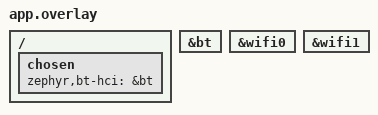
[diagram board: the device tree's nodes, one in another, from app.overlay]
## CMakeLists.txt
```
# SPDX-License-Identifier: Apache-2.0
cmake_minimum_required(VERSION 3.20.0)
find_package(Zephyr REQUIRED HINTS $ENV{ZEPHYR_BASE})
project(nu87_lcd_gateway)
if(CONFIG_GATEWAY_USB_HOST)
  target_sources(app PRIVATE src/usb_host.c)
endif()
if(CONFIG_GATEWAY_IMU)
  target_include_directories(app PRIVATE ../nu87_imu_bringup/include)
  target_sources(app PRIVATE src/imu_live.c ../nu87_imu_bringup/src/imu_device.c)
endif()
target_include_directories(app PRIVATE
  include
  ${ZEPHYR_BASE}/drivers/wifi/ameba
  ../wireless_lcd_common/include
  ../wireless_lcd_common/dfu
)
target_sources(app PRIVATE
  src/main.c
  src/wifi.c
  src/timer_core.c
  src/ameba_timer_thread.c
  src/ameba_irq.c
  src/radio_diagnostics.c
  src/hci_transport_diagnostics.c
  src/ameba_coex_scan.c
  src/http_server.c
  src/http_io.c
  src/http_parse.c
)
if(CONFIG_GATEWAY_NU40_KIT)
  target_sources(app PRIVATE src/ble_kit.c src/smp_relay.c src/alarm_relay.c src/robot_state.c src/ota_disabled.c)
else()
  target_sources(app PRIVATE src/ble_link.c src/ota.c
    ../wireless_lcd_common/dfu/legacy_dfu_client.c)
endif()

# Vendor timer callbacks may take mutexes. Keep them on a private daemon thread
# instead of the pinned SDK's k_timer interrupt callbacks, without editing SDKs.
foreach(timer_api create create_static delete delete_static start stop change_period is_timer_active get_id)
  zephyr_ld_options(-Wl,--wrap=rtos_timer_${timer_api})
endforeach()
# Keep the vendor's strong init_timer_wrapper: it initializes its callback map.

# Realtek HCI uses hardware priority 7; Zephyr reserves one priority level.
zephyr_ld_options(-Wl,--wrap=arch_irq_connect_dynamic)
# Retain the vendor error and heap snapshots before Zephyr maps it to -EAGAIN.
zephyr_ld_options(-Wl,--wrap=wifi_connect_zephyr)
# Observe RF calibration and raw RX counts without changing SDK behavior.
zephyr_ld_options(-Wl,--wrap=rtk_coex_btc_bt_rfk)
zephyr_ld_options(-Wl,--wrap=bt_coex_process_rx_frame)

# Count UART frames before the vendor H4 event pool, preserving the wire bytes.
zephyr_ld_options(-Wl,--wrap=hci_uart_read)
zephyr_ld_options(-Wl,--wrap=UART_LineStatusGet)
```

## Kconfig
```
# SPDX-License-Identifier: Apache-2.0
mainmenu "NU87 Wi-Fi to NU40 BLE LCD gateway"
source "Kconfig.zephyr"
menu "LCD gateway settings"
config GATEWAY_USB_HOST
	bool "Use the on-board USB-UART for HostPC data and control"
	depends on GATEWAY_NU40_KIT
	default n
	help
	  Use authenticated CRC-protected serial RPC instead of the HTTP listener.
	  The shared Realtek RF initializes without AP association or DHCP.
config GATEWAY_IMU
	bool "Read an attached LSM6DS3/LSM6DS3TR-C over PA25/PA26"
	select I2C
	select GPIO
	select PINCTRL
	default n
choice GATEWAY_DISPLAY_PROTOCOL
	prompt "NU40 display firmware protocol"
	default GATEWAY_LCD_LEGACY
config GATEWAY_LCD_LEGACY
	bool "MZSZ-LCD / verified S140 legacy DFU"
config GATEWAY_NU40_KIT
	bool "NU40-KIT-DISPLAY with optional voice and authenticated SMP"
endchoice
config GATEWAY_PEER_ADDRESS
	string "Explicit NU40 LCD Bluetooth address (AA:BB:CC:DD:EE:FF)"
	default ""
config GATEWAY_PEER_ADDRESS_TYPE
	string "LCD Bluetooth address type (random or public)"
	default "random"
config GATEWAY_DFU_ADDRESS
	string "Explicit bootloader Bluetooth address; empty requires same LCD address"
	default ""
config GATEWAY_DFU_ADDRESS_TYPE
	string "Bootloader Bluetooth address type (random or public)"
	default "random"
config GATEWAY_WIFI_SSID
	string "Isolated test Wi-Fi SSID"
	default ""
config GATEWAY_WIFI_PSK
	string "Disposable test Wi-Fi PSK"
	default ""
config GATEWAY_WIFI_CHANNEL
	int "2.4 GHz AP channel (0 scans all channels)"
	range 0 14
	default 0
	help
	  Try the AP's observed channel on the first association attempt. Later
	  attempts scan all channels so a restarted hotspot can change channel.
	  Leave zero to scan all channels from the first attempt.
choice GATEWAY_WIFI_SECURITY
	prompt "Wi-Fi security"
	default GATEWAY_WIFI_SECURITY_OPEN
config GATEWAY_WIFI_SECURITY_OPEN
	bool "Open isolated test network"
config GATEWAY_WIFI_SECURITY_PSK
	bool "WPA2-PSK isolated test network"
endchoice
config GATEWAY_ALLOW_INSECURE_TEST_PSK
	bool "Acknowledge the AmebaD unverified entropy source for test WPA2"
	depends on GATEWAY_WIFI_SECURITY_PSK
	default n
config GATEWAY_WIFI_CONNECT_DELAY_MS
	int
	default 500
config GATEWAY_WIFI_CONNECT_RETRY_SECONDS
	int
	default 10
config GATEWAY_WIFI_CONNECT_TIMEOUT_SECONDS
	int
	default 60
config GATEWAY_WIFI_WORK_STACK_SIZE
	int
	default 4096
config GATEWAY_WIFI_WORK_PRIORITY
	int
	default 7
config GATEWAY_TIMER_STACK_SIZE
	int "Vendor software timer daemon stack size"
	range 2048 16384
	default 6144
config GATEWAY_HTTP_PORT
	int "HTTP port"
	range 1 65535
	default 8080
config GATEWAY_API_TOKEN
	string "Local API bearer token; empty disables mutating HTTP requests"
	default ""
config GATEWAY_NU40_PASSKEY
	string "Private six-digit NU40 pairing passkey (empty disables SMP relay)"
	depends on GATEWAY_NU40_KIT
	default ""
config GATEWAY_LOG_LEVEL
	int
	range 0 4
	default 3
endmenu
```

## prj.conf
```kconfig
CONFIG_CONSOLE=y
CONFIG_SERIAL=y
CONFIG_UART_CONSOLE=y
CONFIG_PRINTK=y
CONFIG_LOG=y
CONFIG_LOG_DEFAULT_LEVEL=3
# HTTP parsing and the vendor's synchronous Wi-Fi transmit path share main.
CONFIG_MAIN_STACK_SIZE=12288
CONFIG_INIT_STACKS=y
CONFIG_THREAD_STACK_INFO=y
CONFIG_SYSTEM_WORKQUEUE_STACK_SIZE=2048
CONFIG_ASSERT=y
CONFIG_NETWORKING=y
CONFIG_NET_IPV4=y
CONFIG_NET_IPV6=n
CONFIG_NET_TCP=y
CONFIG_NET_UDP=y
CONFIG_NET_SOCKETS=y
CONFIG_NET_CONNECTION_MANAGER=y
# The application's Wi-Fi state machine owns disconnect/retry transitions.
CONFIG_NET_CONNECTION_MANAGER_AUTO_IF_DOWN=n
CONFIG_NET_DHCPV4=y
CONFIG_WIFI=y
CONFIG_WIFI_AMEBA=y
CONFIG_NET_L2_WIFI_MGMT=y
CONFIG_RTK_WIFI_STA_AUTO_DHCPV4=y
CONFIG_NOCACHE_MEMORY=y
CONFIG_HEAP_MEM_POOL_SIZE=65536
CONFIG_SYS_HEAP_RUNTIME_STATS=y
CONFIG_NET_PKT_RX_COUNT=10
CONFIG_NET_PKT_TX_COUNT=10
CONFIG_NET_BUF_RX_COUNT=20
CONFIG_NET_BUF_TX_COUNT=32
CONFIG_NET_MAX_CONTEXTS=10
CONFIG_NET_MAX_CONN=10
CONFIG_BT=y
CONFIG_BT_CENTRAL=y
CONFIG_BT_GATT_CLIENT=y
CONFIG_BT_MAX_CONN=1
CONFIG_BT_SMP=y
CONFIG_BT_SHELL=n
CONFIG_REALTEK_AMEBA_ZEPHYR_BT=y
CONFIG_BT_COEXIST=y
# Realtek's internal HCI UART uses dynamic IRQ registration.
CONFIG_DYNAMIC_INTERRUPTS=y
# This AmebaD port has no verified hardware entropy source. Bring-up only.
CONFIG_TEST_RANDOM_GENERATOR=y
CONFIG_BT_GATT_AUTO_DISCOVER_CCC=y
CONFIG_BT_DEVICE_NAME="MZSZ-LCD-Gateway"
CONFIG_THREAD_NAME=y
CONFIG_LOG_MODE_DEFERRED=y
CONFIG_LOG_BUFFER_SIZE=4096
CONFIG_NET_MGMT_EVENT_QUEUE_SIZE=16
CONFIG_NET_MGMT_EVENT_QUEUE_TIMEOUT=5000
# LCD writes remain <=20 bytes; optional audio notifications require MTU >=179.
CONFIG_BT_L2CAP_TX_MTU=247
CONFIG_BT_BUF_ACL_RX_SIZE=251
```

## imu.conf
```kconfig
# Real sensor only. Requires imu.overlay and the bounded repeated-START fix.
CONFIG_GATEWAY_IMU=y
```

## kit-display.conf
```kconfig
# Current mzsz94/nu40-ble-display protocol; keep its installed firmware.
# No S140 legacy DFU, power control or automatic peer selection.
CONFIG_GATEWAY_NU40_KIT=y
```

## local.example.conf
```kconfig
# Copy to ignored local.conf and fill in values. Default stays unconfigured.
# Use only an isolated test AP: the pinned AmebaD port lacks verified entropy.
CONFIG_GATEWAY_WIFI_SSID=""
CONFIG_GATEWAY_WIFI_SECURITY_OPEN=y
CONFIG_GATEWAY_API_TOKEN=""
# Explicit peer identity required; a matching advertised name is insufficient.
CONFIG_GATEWAY_PEER_ADDRESS=""
CONFIG_GATEWAY_PEER_ADDRESS_TYPE="random"
# Empty means the bootloader must have exactly the same address/type.
# Official unbonded legacy bootloaders commonly increment the last address byte.
# Inspect the bootloader identity and configure it explicitly; no automatic
# address arithmetic or name-only trust is performed by this gateway.
CONFIG_GATEWAY_DFU_ADDRESS=""
CONFIG_GATEWAY_DFU_ADDRESS_TYPE="random"
```

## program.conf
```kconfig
# Zephyr's default console is the Ameba LogUART at 1500000 baud.
CONFIG_BUILD_OUTPUT_BIN=y
# Include pinned Realtek KM0 firmware and generate the runnable merged image.
CONFIG_SOC_AMEBA_NP_IMAGE=y
```

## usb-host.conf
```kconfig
# USB owns the API; initialize the shared RF without joining an access point.
CONFIG_GATEWAY_USB_HOST=y
# Keep vendor startup diagnostics visible until RF is ready. usb_host.c then
# disables this backend before sending framed traffic, preventing interleaving.
CONFIG_LOG_BACKEND_UART=y
CONFIG_LOG_PRINTK=y
```

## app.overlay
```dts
/ {
	chosen { zephyr,bt-hci = &bt; };
};
&bt { status = "okay"; };
&wifi0 { status = "okay"; };
&wifi1 { status = "okay"; };
```

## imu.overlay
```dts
/* SPDX-License-Identifier: Apache-2.0 */
#include <zephyr/dt-bindings/pinctrl/amebad-pinctrl.h>
&pinctrl {
	imu_i2c_default: imu_i2c_default {
		group1 {
			pinmux = <AMEBA_PINMUX('A', 25, AMEBA_I2C)>,
				 <AMEBA_PINMUX('A', 26, AMEBA_I2C)>;
			bias-pull-up;
		};
	};
};
&i2c0 {
	status = "okay";
	clock-frequency = <I2C_BITRATE_STANDARD>;
	pinctrl-0 = <&imu_i2c_default>;
	pinctrl-names = "default";
};
```

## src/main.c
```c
/* SPDX-License-Identifier: Apache-2.0 */
#include "gateway_link.h"
#include "gateway_http.h"
#include "gateway_imu.h"
#include "gateway_usb.h"
#include <zephyr/kernel.h>
#include <zephyr/logging/log.h>
LOG_MODULE_REGISTER(lcd_gateway, LOG_LEVEL_INF);
int main(void)
{
	LOG_INF("NU87 Wi-Fi/BLE LCD gateway: isolated test LAN only");
	gateway_imu_start();
	int rc = gateway_radio_init();
	if (rc) { LOG_ERR("Radio initialization failed: %d", rc); return rc; }
#if defined(CONFIG_GATEWAY_USB_HOST)
	gateway_usb_run();
#else
	gateway_http_run();
#endif
	return 0;
}
```

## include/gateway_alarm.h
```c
/* SPDX-License-Identifier: Apache-2.0 */
#ifndef WALLABY_GATEWAY_ALARM_H
#define WALLABY_GATEWAY_ALARM_H
#include <stdbool.h>
#include <stddef.h>
#include <stdint.h>
struct bt_conn;
int gateway_alarm_prepare(struct bt_conn *conn);
void gateway_alarm_disconnected(struct bt_conn *conn);
bool gateway_alarm_drained(void);
int gateway_alarm_set(bool active);
int gateway_alarm_status(char *json, size_t capacity);
#endif
```

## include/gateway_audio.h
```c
/* SPDX-License-Identifier: Apache-2.0 */
#ifndef WALLABY_GATEWAY_AUDIO_H
#define WALLABY_GATEWAY_AUDIO_H
#include <stdbool.h>
#include <stddef.h>
#include <stdint.h>
#include <string.h>

#define GATEWAY_AUDIO_FRAME_SIZE 176U
#define GATEWAY_AUDIO_RING_FRAMES 64U
#define GATEWAY_AUDIO_DRAIN_FRAMES 32U
#define GATEWAY_AUDIO_MIN_MTU 179U
#define GATEWAY_AUDIO_CTRL_UUID_VAL BT_UUID_128_ENCODE(0x90e2c003, 0x3c0d, 0x4ef3, 0x9d78, 0x574cd1a64087)
#define GATEWAY_AUDIO_DATA_UUID_VAL BT_UUID_128_ENCODE(0x90e2c004, 0x3c0d, 0x4ef3, 0x9d78, 0x574cd1a64087)

/* Caller supplies synchronization. Independent ADPCM frames never inherit a
 * predictor from a lost frame. No partial/truncated notifications are queued. */
struct gateway_audio_ring {
 uint8_t frames[GATEWAY_AUDIO_RING_FRAMES][GATEWAY_AUDIO_FRAME_SIZE];
 uint32_t session, next_sequence, received, dropped;
 size_t head, queued;
 bool available, running;
 int error;
};

static inline uint32_t gateway_audio_u32(const uint8_t *p)
{ return (uint32_t)p[0] | (uint32_t)p[1] << 8 | (uint32_t)p[2] << 16 | (uint32_t)p[3] << 24; }
static inline void gateway_audio_add(uint32_t *value, uint32_t amount)
{ *value = UINT32_MAX - *value < amount ? UINT32_MAX : *value + amount; }

static inline bool gateway_audio_frame_valid(const uint8_t *p, size_t size)
{
 return p != NULL && size == GATEWAY_AUDIO_FRAME_SIZE && p[0] == 'W' && p[1] == 'A' &&
  p[2] == 1 && p[3] == 0 && p[14] <= 88 && p[15] == 0 && (p[175] & 0xf0) == 0;
}

static inline void gateway_audio_reset(struct gateway_audio_ring *r, uint32_t session)
{
 r->session = session; r->next_sequence = 0; r->received = r->dropped = 0;
 r->head = r->queued = 0; r->running = true; r->error = 0;
}

static inline bool gateway_audio_push(struct gateway_audio_ring *r, const uint8_t *p, size_t size)
{
 if (!r->running) { return false; }
 if (!gateway_audio_frame_valid(p, size) || gateway_audio_u32(p + 4) != r->session) {
  gateway_audio_add(&r->dropped, 1); return false;
 }
 uint32_t sequence = gateway_audio_u32(p + 8);
 /* Sessions are bounded; never let sequence wrap re-admit stale data. */
 if (sequence < r->next_sequence || sequence == UINT32_MAX) {
  gateway_audio_add(&r->dropped, 1); return false;
 }
 gateway_audio_add(&r->dropped, sequence - r->next_sequence);
 r->next_sequence = sequence + 1;
 gateway_audio_add(&r->received, 1);
 if (r->queued == GATEWAY_AUDIO_RING_FRAMES) {
  r->head = (r->head + 1) % GATEWAY_AUDIO_RING_FRAMES;
  r->queued--; gateway_audio_add(&r->dropped, 1);
 }
 memcpy(r->frames[(r->head + r->queued) % GATEWAY_AUDIO_RING_FRAMES], p, size);
 r->queued++;
 return true;
}

static inline size_t gateway_audio_pop(struct gateway_audio_ring *r, uint8_t *out, size_t capacity)
{
 size_t count = capacity / GATEWAY_AUDIO_FRAME_SIZE;
 if (count > GATEWAY_AUDIO_DRAIN_FRAMES) { count = GATEWAY_AUDIO_DRAIN_FRAMES; }
 if (count > r->queued) { count = r->queued; }
 if (out == NULL) { return 0; }
 for (size_t i = 0; i < count; i++) {
  memcpy(out + i * GATEWAY_AUDIO_FRAME_SIZE, r->frames[r->head], GATEWAY_AUDIO_FRAME_SIZE);
  r->head = (r->head + 1) % GATEWAY_AUDIO_RING_FRAMES;
 }
 r->queued -= count;
 return count * GATEWAY_AUDIO_FRAME_SIZE;
}

int gateway_audio_status(char *json, size_t capacity);
int gateway_audio_start(uint32_t session);
int gateway_audio_stop(void);
int gateway_audio_pause(void);
bool gateway_audio_available(void);
size_t gateway_audio_chunk(uint8_t *data, size_t capacity);
#endif
```

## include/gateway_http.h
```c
/* SPDX-License-Identifier: Apache-2.0 */
#ifndef GATEWAY_HTTP_H
#define GATEWAY_HTTP_H
#include <stddef.h>
#include <stdint.h>
#include <stdbool.h>
#define HTTP_HEADER_CAPACITY 1536
#define OTA_DESCRIPTOR_SIZE 80
struct http_request {
	char method[8];
	char path[96];
	char bearer[129];
	size_t content_length;
	bool keep_alive;
};
/* Strict request framing; bounded sequential keep-alive, no chunking. */
int http_parse_request(char *header, struct http_request *request);
int http_send_all(int socket, const void *data, size_t length);
int http_read_exact(int socket, void *data, size_t length);
int http_read_before(int socket, void *data, size_t length, int64_t deadline);
int http_fetch_image(uint32_t ipv4, uint16_t port, const char *id,
		     uint32_t offset, uint32_t total, uint8_t *data, size_t length);
void gateway_http_run(void);
typedef void (*gateway_api_reply_fn)(void *user, int code, const void *body,
				     size_t length, const char *type);
/* The USB build uses the same authenticated routes. Only one transport owns
 * the handler's static buffers in a given firmware build. */
bool gateway_api_authenticated(const char *token);
void gateway_api_execute(const char *method, const char *path, const uint8_t *body,
			 size_t length, gateway_api_reply_fn reply, void *user);
int gateway_ota_start(uint32_t ipv4, const uint8_t descriptor[OTA_DESCRIPTOR_SIZE]);
int gateway_ota_cancel(void);
bool gateway_ota_busy(void);
void gateway_ota_status(char *buffer, size_t capacity);
#endif
```

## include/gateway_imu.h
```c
/* SPDX-License-Identifier: Apache-2.0 */
#ifndef GATEWAY_IMU_H
#define GATEWAY_IMU_H
#include <stddef.h>
#include <zephyr/sys/printk.h>
#ifdef CONFIG_GATEWAY_IMU
void gateway_imu_start(void);
int gateway_imu_status(char *buffer, size_t capacity);
#else
static inline void gateway_imu_start(void) {}
static inline int gateway_imu_status(char *buffer, size_t capacity)
{
	return snprintk(buffer, capacity, "{\"configured\":false,\"ready\":false,"
		       "\"fresh\":false,\"source\":\"nu87-i2c\"}");
}
#endif
#endif
```

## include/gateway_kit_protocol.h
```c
/* SPDX-License-Identifier: Apache-2.0 */
/* Vendored from https://github.com/mzsz94/nu40-ble-display
 * commit 230a1300d121b3bf25d3125a0cf247679148a40a, shared/ble_display_protocol.h.
 * Original framing helper is unchanged; local filename differs.
 * See NU40-KIT-LICENSE.txt for the upstream Apache-2.0 license.
 */
#ifndef BLE_DISPLAY_PROTOCOL_H_
#define BLE_DISPLAY_PROTOCOL_H_

#include <stdbool.h>
#include <stddef.h>
#include <stdint.h>
#include <string.h>

/* No larger MTU is needed: every write fits the default 20-byte ATT payload. */
#define BLE_DISPLAY_VERSION 1U
#define BLE_DISPLAY_TEXT 1U
#define BLE_DISPLAY_ACK 2U
#define BLE_DISPLAY_CHUNK 14U
#define BLE_DISPLAY_MAX_TEXT 84U
#define BLE_DISPLAY_FRAME_MAX 20U
#define BLE_DISPLAY_ACK_SIZE 5U
#define BLE_DISPLAY_TIMEOUT_MS 2000U
#define BLE_DISPLAY_COLUMNS 21U
#define BLE_DISPLAY_ROWS 4U

#define BLE_DISPLAY_UUID_SERVICE_VAL \
	BT_UUID_128_ENCODE(0x90e2c000, 0x3c0d, 0x4ef3, 0x9d78, 0x574cd1a64087)
#define BLE_DISPLAY_UUID_ACK_VAL \
	BT_UUID_128_ENCODE(0x90e2c001, 0x3c0d, 0x4ef3, 0x9d78, 0x574cd1a64087)
#define BLE_DISPLAY_UUID_TEXT_VAL \
	BT_UUID_128_ENCODE(0x90e2c002, 0x3c0d, 0x4ef3, 0x9d78, 0x574cd1a64087)

enum ble_display_result {
	BLE_DISPLAY_WAIT = 0,
	BLE_DISPLAY_COMPLETE = 1,
	BLE_DISPLAY_INVALID = -1,
	BLE_DISPLAY_ORDER = -2,
	BLE_DISPLAY_EXPIRED = -3,
};

enum ble_display_status {
	BLE_DISPLAY_OK = 0,
	BLE_DISPLAY_BAD_TEXT = 1,
	BLE_DISPLAY_OLED_ERROR = 2,
	BLE_DISPLAY_BUSY = 3,
};

struct ble_display_rx {
	char text[BLE_DISPLAY_MAX_TEXT + 1];
	uint32_t started_ms;
	uint16_t sequence;
	uint8_t total;
	uint8_t received;
	bool active;
};

static inline uint16_t ble_display_u16(const uint8_t *bytes)
{
	return (uint16_t)bytes[0] | ((uint16_t)bytes[1] << 8);
}

static inline bool ble_display_valid_text(const char *text, size_t length)
{
	if (text == NULL || length == 0 || length > BLE_DISPLAY_MAX_TEXT) {
		return false;
	}
	for (size_t i = 0; i < length; i++) {
		uint8_t c = (uint8_t)text[i];

		if (c != '\n' && (c < 32 || c > 126)) {
			return false;
		}
	}
	return true;
}

/* Render only complete messages that fit the 128x32 display's 6x8 font. */
static inline bool ble_display_split_lines(const char *text, size_t length,
					   char lines[BLE_DISPLAY_ROWS][BLE_DISPLAY_COLUMNS + 1])
{
	size_t row = 0, column = 0;

	if (lines == NULL || !ble_display_valid_text(text, length)) {
		return false;
	}
	memset(lines, 0, BLE_DISPLAY_ROWS * (BLE_DISPLAY_COLUMNS + 1));
	for (size_t i = 0; i < length; i++) {
		if (text[i] == '\n') {
			row++;
			column = 0;
			continue;
		}
		if (column == BLE_DISPLAY_COLUMNS) {
			row++;
			column = 0;
		}
		if (row >= BLE_DISPLAY_ROWS) {
			return false;
		}
		lines[row][column++] = text[i];
	}
	return true;
}

/* Return frame length, or zero for invalid input. */
static inline size_t ble_display_build_text(const char *text, size_t length, uint16_t sequence,
					   uint8_t chunk, uint8_t out[BLE_DISPLAY_FRAME_MAX])
{
	size_t offset = (size_t)chunk * BLE_DISPLAY_CHUNK;
	size_t payload;

	if (out == NULL || !ble_display_valid_text(text, length) || offset >= length) {
		return 0;
	}
	payload = length - offset;
	if (payload > BLE_DISPLAY_CHUNK) {
		payload = BLE_DISPLAY_CHUNK;
	}
	out[0] = BLE_DISPLAY_VERSION;
	out[1] = BLE_DISPLAY_TEXT;
	out[2] = sequence & 0xff;
	out[3] = sequence >> 8;
	out[4] = chunk;
	out[5] = length;
	memcpy(out + 6, text + offset, payload);
	return 6 + payload;
}

static inline void ble_display_rx_reset(struct ble_display_rx *rx)
{
	memset(rx, 0, sizeof(*rx));
}

/* A complete text is exposed only after every in-order fragment is received. */
static inline enum ble_display_result ble_display_receive(struct ble_display_rx *rx,
							  const uint8_t *frame, size_t length,
							  uint32_t now_ms)
{
	size_t offset, payload;
	uint16_t sequence;
	uint8_t total, chunk;

	if (rx == NULL) {
		return BLE_DISPLAY_INVALID;
	}
	if (frame == NULL || length < 7 || length > BLE_DISPLAY_FRAME_MAX ||
	    frame[0] != BLE_DISPLAY_VERSION || frame[1] != BLE_DISPLAY_TEXT) {
		rx->active = false;
		return BLE_DISPLAY_INVALID;
	}
	sequence = ble_display_u16(frame + 2);
	chunk = frame[4];
	total = frame[5];
	offset = (size_t)chunk * BLE_DISPLAY_CHUNK;
	if (total == 0 || total > BLE_DISPLAY_MAX_TEXT || offset >= total) {
		rx->active = false;
		return BLE_DISPLAY_INVALID;
	}
	payload = total - offset;
	if (payload > BLE_DISPLAY_CHUNK) {
		payload = BLE_DISPLAY_CHUNK;
	}
	if (length != 6 + payload ||
	    !ble_display_valid_text((const char *)frame + 6, payload)) {
		rx->active = false;
		return BLE_DISPLAY_INVALID;
	}
	if (chunk == 0) {
		rx->sequence = sequence;
		rx->total = total;
		rx->received = 0;
		rx->started_ms = now_ms;
		rx->active = true;
	} else {
		if (!rx->active || rx->sequence != sequence || rx->total != total ||
		    rx->received != offset) {
			rx->active = false;
			return BLE_DISPLAY_ORDER;
		}
		if ((uint32_t)(now_ms - rx->started_ms) > BLE_DISPLAY_TIMEOUT_MS) {
			rx->active = false;
			return BLE_DISPLAY_EXPIRED;
		}
	}
	memcpy(rx->text + offset, frame + 6, payload);
	rx->received += payload;
	if (rx->received == rx->total) {
		rx->text[rx->total] = '\0';
		rx->active = false;
		return BLE_DISPLAY_COMPLETE;
	}
	return BLE_DISPLAY_WAIT;
}

static inline void ble_display_build_ack(uint16_t sequence, uint8_t status,
					 uint8_t out[BLE_DISPLAY_ACK_SIZE])
{
	out[0] = BLE_DISPLAY_VERSION;
	out[1] = BLE_DISPLAY_ACK;
	out[2] = sequence & 0xff;
	out[3] = sequence >> 8;
	out[4] = status;
}

static inline bool ble_display_parse_ack(const uint8_t *frame, size_t length,
					 uint16_t *sequence, uint8_t *status)
{
	if (frame == NULL || length != BLE_DISPLAY_ACK_SIZE ||
	    frame[0] != BLE_DISPLAY_VERSION || frame[1] != BLE_DISPLAY_ACK ||
	    frame[4] > BLE_DISPLAY_BUSY || sequence == NULL || status == NULL) {
		return false;
	}
	*sequence = ble_display_u16(frame + 2);
	*status = frame[4];
	return true;
}

#endif /* BLE_DISPLAY_PROTOCOL_H_ */
```

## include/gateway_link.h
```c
/* SPDX-License-Identifier: Apache-2.0 */
#ifndef MZSZ_GATEWAY_LINK_H
#define MZSZ_GATEWAY_LINK_H
#include <stdbool.h>
#include <stddef.h>
#include <stdint.h>
#include "lcd_protocol.h"
#if defined(CONFIG_GATEWAY_NU40_KIT)
#include "gateway_audio.h"
#include "gateway_smp.h"
#include "gateway_alarm.h"
#include "gateway_robot.h"
#endif

struct gateway_state {
	bool wifi_connected;
	char wifi_ipv4[16];
	bool ble_configured;
	bool ble_connected;
	bool lcd_ready;
	bool dfu_ready;
	char peer_addr[32];
	int last_error;
};

/* RX-context callback: copy/queue the data and return; never block here. */
typedef void (*gateway_dfu_notify_fn)(const uint8_t *data, size_t len, void *user);
int gateway_radio_init(void);
/* Diagnostic stage must be a non-sensitive, static string. */
void gateway_radio_diagnostics(const char *stage);
void gateway_radio_coex_diagnostics(void);
int gateway_hci_diagnostics(char *json, size_t capacity);
int gateway_hci_transport_diagnostics(char *json, size_t capacity);
int gateway_coex_scan_diagnostics(char *json, size_t capacity);
/* Observe HCI framing only; vendor coexistence work runs on its own thread. */
void gateway_coex_scan_tx(uint8_t type, const uint8_t *data, uint16_t length);
void gateway_coex_scan_rx(uint8_t type, const uint8_t *data, uint16_t length);
/* H4 RX thread only: serialize native coexistence processing with reports. */
void gateway_coex_scan_rx_begin(void);
void gateway_coex_scan_rx_end(void);
void gateway_get_state(struct gateway_state *state);
/* One blocking request at a time. Success means a matching completion status
 * arrived; status[4] still carries the peripheral's LCD_RESULT_* result.
 * No automatic retry or replay is performed on timeout/disconnect.
 */
int gateway_lcd_command(const uint8_t *data, size_t len,
			uint8_t status[LCD_STATUS_SIZE], int timeout_ms);

/* NU40-KIT-DISPLAY mode: bounded discovery and explicit, fresh peer selection.
 * Candidates returns a JSON array's byte count or a negative error. Selection
 * starts connection asynchronously; display succeeds only after matching ACK.
 */
#if defined(CONFIG_GATEWAY_NU40_KIT)
int gateway_peer_candidates(char *json, size_t capacity);
int gateway_scan_diagnostics(char *json, size_t capacity);
int gateway_kit_diagnostics(char *json, size_t capacity);
/* Queue an active/passive scan-mode change; never interrupt an active peer. */
int gateway_scan_mode(const char *mode);
int gateway_select_peer(const char *address, const char *type);
int gateway_display_text(const uint8_t *text, size_t len, int timeout_ms);
#endif
int gateway_dfu_enter(void);
int gateway_dfu_control(const uint8_t *data, size_t len);
int gateway_dfu_packet(const uint8_t *data, size_t len);
void gateway_dfu_set_notify_callback(gateway_dfu_notify_fn callback, void *user);
/* Leave DFU transport mode after a finished/failed transfer. No device reset
 * or activation command is sent. Subsequent scanning targets the LCD identity.
 */
void gateway_dfu_leave(void);

/* Internal Wi-Fi module interface; also useful to the HTTP listener. */
int gateway_wifi_start(void);
bool gateway_wifi_ipv4_ready(void);
int gateway_wifi_address(char *buffer, size_t capacity);
#endif
```

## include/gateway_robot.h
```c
/* SPDX-License-Identifier: Apache-2.0 */
#ifndef WALLABY_GATEWAY_ROBOT_H
#define WALLABY_GATEWAY_ROBOT_H
#include <stdbool.h>
#include <stddef.h>
int gateway_robot_command(const char *command);
int gateway_robot_status(char *json, size_t capacity, bool accepted);
void gateway_robot_alert(bool active);
#endif
```

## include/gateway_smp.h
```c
/* SPDX-License-Identifier: Apache-2.0 */
#ifndef WALLABY_GATEWAY_SMP_H
#define WALLABY_GATEWAY_SMP_H
#include <stdbool.h>
#include <stddef.h>
#include <stdint.h>
#include <string.h>
#define GATEWAY_SMP_MAX 1024U
struct bt_conn;
struct gateway_smp_rx {
 uint8_t request[8], data[GATEWAY_SMP_MAX];
 size_t used, expected;
};
static inline size_t gateway_smp_length(const uint8_t *p)
{ return 8U + ((size_t)p[2] << 8) + p[3]; }
static inline bool gateway_smp_request_valid(const uint8_t *p, size_t size)
{
 return p != NULL && size >= 8 && size <= GATEWAY_SMP_MAX &&
  (p[0] == 0 || p[0] == 2) && p[1] == 0 && gateway_smp_length(p) == size;
}
/* 1 complete, 0 more required, 2 unrelated reply, -1 invalid framing. */
static inline int gateway_smp_receive(struct gateway_smp_rx *r, const uint8_t *p, size_t size)
{
 if (p == NULL || size == 0) { return -1; }
 if (r->used == 0) {
  if (size < 8) { return -1; }
  if (p[0] != r->request[0] + 1 || p[1] != 0 || memcmp(p + 4, r->request + 4, 4) != 0) { return 2; }
  r->expected = gateway_smp_length(p);
  if (r->expected > GATEWAY_SMP_MAX) { return -1; }
 }
 if (size > r->expected - r->used) { return -1; }
 memcpy(r->data + r->used, p, size); r->used += size;
 return r->used == r->expected ? 1 : 0;
}
int gateway_smp_prepare(struct bt_conn *conn);
int gateway_smp_auth_init(void);
void gateway_smp_disconnected(struct bt_conn *conn);
bool gateway_smp_drained(void);
bool gateway_smp_available(void);
bool gateway_smp_busy(void);
int gateway_smp_transaction(const uint8_t *request, size_t size, uint8_t *response, size_t capacity);
#endif
```

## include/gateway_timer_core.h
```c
/* SPDX-License-Identifier: Apache-2.0 */
#ifndef GATEWAY_TIMER_CORE_H
#define GATEWAY_TIMER_CORE_H

#include <stdbool.h>
#include <stdint.h>

/* All operations require the caller's lock. Only the daemon dispatches and
 * completes callbacks. Opaque handles remain valid until delete is accepted;
 * reusing a deleted handle after allocation reuses its address is caller misuse.
 */
struct gateway_timer {
	struct gateway_timer *next;
	void (*callback)(void *);
	uint32_t id;
	uint32_t interval_ms;
	uint32_t generation;
	uint32_t dispatched_generation;
	int64_t deadline_ms;
	bool periodic;
	bool active;
	bool running;
	bool retired;
};

struct gateway_timer_core {
	struct gateway_timer *head;
};

enum gateway_timer_delete_result {
	GATEWAY_TIMER_DELETE_INVALID = -1,
	GATEWAY_TIMER_DELETE_DEFERRED = 0,
	GATEWAY_TIMER_DELETE_RECLAIM = 1,
};

void gateway_timer_add(struct gateway_timer_core *core, struct gateway_timer *timer);
struct gateway_timer *gateway_timer_find(struct gateway_timer_core *core, const void *handle);
bool gateway_timer_arm(struct gateway_timer_core *core, const void *handle,
		       uint32_t interval_ms, int64_t now_ms);
bool gateway_timer_stop(struct gateway_timer_core *core, const void *handle);
enum gateway_timer_delete_result gateway_timer_retire(struct gateway_timer_core *core,
						      const void *handle);
struct gateway_timer *gateway_timer_dispatch(struct gateway_timer_core *core,
					     int64_t now_ms, int64_t *wait_ms);
bool gateway_timer_complete(struct gateway_timer_core *core, struct gateway_timer *timer,
			    int64_t now_ms);

#endif
```

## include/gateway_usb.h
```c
/* SPDX-License-Identifier: Apache-2.0 */
#ifndef WALLABY_GATEWAY_USB_H
#define WALLABY_GATEWAY_USB_H
void gateway_usb_run(void);
#endif
```

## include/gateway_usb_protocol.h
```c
/* SPDX-License-Identifier: Apache-2.0 */
#ifndef WALLABY_GATEWAY_USB_PROTOCOL_H
#define WALLABY_GATEWAY_USB_PROTOCOL_H
#include <stdbool.h>
#include <stddef.h>
#include <stdint.h>
#include <string.h>

/* COBS-delimited frames coexist with boot text. CRC covers the whole decoded
 * message. A fresh authenticated HELLO owns a session; mutations are never
 * retried. The largest response is 32 complete 176-byte microphone frames. */
#define USB_RPC_HEADER 20U
#define USB_RPC_BODY_MAX 5632U
#define USB_RPC_REQUEST_MAX 1024U
#define USB_RPC_WIRE_MAX 6144U
#define USB_RPC_REQUEST 1U
#define USB_RPC_RESPONSE 2U
#define USB_RPC_HELLO 0U
#define USB_RPC_GET 1U
#define USB_RPC_POST 2U

struct usb_rpc_session {
	uint32_t owner;
	uint32_t sequence;
};

/* Call only AFTER authentication. Consume a new sequence before executing a
 * mutation, so losing its response cannot cause duplicate execution. */
static inline bool usb_rpc_accept(struct usb_rpc_session *session, uint32_t owner,
				  uint32_t sequence, bool hello)
{
	if (!owner || !sequence) { return false; }
	if (hello) {
		if (sequence != 1 || session->owner == owner) { return false; }
		session->owner = owner;
	} else if (session->owner != owner || sequence <= session->sequence) {
		return false;
	}
	session->sequence = sequence;
	return true;
}

static inline uint16_t usb_rpc_u16(const uint8_t *p)
{
	return p[0] | (uint16_t)p[1] << 8;
}

static inline uint32_t usb_rpc_u32(const uint8_t *p)
{
	return p[0] | (uint32_t)p[1] << 8 | (uint32_t)p[2] << 16 | (uint32_t)p[3] << 24;
}

static inline void usb_rpc_put16(uint8_t *p, uint16_t value)
{
	p[0] = value; p[1] = value >> 8;
}

static inline void usb_rpc_put32(uint8_t *p, uint32_t value)
{
	p[0] = value; p[1] = value >> 8; p[2] = value >> 16; p[3] = value >> 24;
}

static inline uint32_t usb_rpc_crc(const uint8_t *data, size_t length)
{
	uint32_t crc = UINT32_MAX;
	for (size_t i = 0; i < length; i++) {
		crc ^= data[i];
		for (unsigned bit = 0; bit < 8; bit++) {
			crc = (crc >> 1) ^ (0xedb88320U & (0U - (crc & 1U)));
		}
	}
	return ~crc;
}

static inline size_t usb_rpc_encode(const uint8_t *data, size_t length,
				    uint8_t *out, size_t capacity)
{
	if (capacity < 1) { return 0; }
	size_t code_at = 0, used = 1;
	uint8_t code = 1;
	for (size_t i = 0; i < length; i++) {
		if (data[i] == 0) {
			out[code_at] = code;
			if (used >= capacity) { return 0; }
			code_at = used++; code = 1;
		} else {
			if (used >= capacity) { return 0; }
			out[used++] = data[i];
			if (++code == 255) {
				out[code_at] = code;
				if (used >= capacity) { return 0; }
				code_at = used++; code = 1;
			}
		}
	}
	out[code_at] = code;
	return used;
}

static inline size_t usb_rpc_decode(const uint8_t *data, size_t length,
				    uint8_t *out, size_t capacity)
{
	size_t at = 0, used = 0;
	while (at < length) {
		uint8_t code = data[at++];
		if (!code || (size_t)code - 1 > length - at ||
		    (size_t)code - 1 > capacity - used) { return 0; }
		for (unsigned i = 1; i < code; i++) {
			if (!data[at]) { return 0; }
			out[used++] = data[at++];
		}
		if (code != 255 && at < length) {
			if (used >= capacity) { return 0; }
			out[used++] = 0;
		}
	}
	return used;
}

struct usb_rpc_request {
	uint32_t session, sequence;
	uint16_t method;
	char path[96], token[129];
	const uint8_t *body;
	size_t length;
};

static inline bool usb_rpc_parse(const uint8_t *data, size_t length,
				 struct usb_rpc_request *request)
{
	if (length < USB_RPC_HEADER + 4 || memcmp(data, "MW\x01\x01", 4) ||
	    data[18] || data[19] || !usb_rpc_u32(data + 4) || !usb_rpc_u32(data + 8)) {
		return false;
	}
	uint16_t method = usb_rpc_u16(data + 12), size = usb_rpc_u16(data + 16);
	size_t path = data[14], token = data[15];
	if (method > USB_RPC_POST || path >= sizeof(request->path) || token < 16 ||
	    token >= sizeof(request->token) || size > USB_RPC_REQUEST_MAX ||
	    length != USB_RPC_HEADER + path + token + size + 4 ||
	    usb_rpc_u32(data + length - 4) != usb_rpc_crc(data, length - 4)) { return false; }
	if ((method == USB_RPC_HELLO && (path || size)) ||
	    (method != USB_RPC_HELLO && (path < 4 || memcmp(data + USB_RPC_HEADER, "/v1/", 4)))) {
		return false;
	}
	for (size_t i = 0; i < path + token; i++) {
		uint8_t byte = data[USB_RPC_HEADER + i];
		if (byte < 33 || byte > 126) { return false; }
	}
	request->session = usb_rpc_u32(data + 4);
	request->sequence = usb_rpc_u32(data + 8);
	request->method = method;
	memcpy(request->path, data + USB_RPC_HEADER, path); request->path[path] = 0;
	memcpy(request->token, data + USB_RPC_HEADER + path, token); request->token[token] = 0;
	request->body = data + USB_RPC_HEADER + path + token;
	request->length = size;
	return true;
}

#endif
```

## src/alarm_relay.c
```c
/* SPDX-License-Identifier: Apache-2.0 */
/* The output firmware ACK, not ATT write completion, confirms a warning. */
#include <errno.h>
#include <stdio.h>
#include <string.h>
#include <zephyr/kernel.h>
#include <zephyr/bluetooth/conn.h>
#include <zephyr/bluetooth/gatt.h>
#include "gateway_alarm.h"
#include "gateway_audio.h"
#include "gateway_kit_protocol.h"
#include "gateway_robot.h"

static struct bt_uuid_128 alarm_service = BT_UUID_INIT_128(BLE_DISPLAY_UUID_SERVICE_VAL);
static struct bt_uuid_128 alarm_control_uuid = BT_UUID_INIT_128(BT_UUID_128_ENCODE(
 0x90e2c005, 0x3c0d, 0x4ef3, 0x9d78, 0x574cd1a64087));
static struct bt_uuid_128 alarm_ack_uuid = BT_UUID_INIT_128(BT_UUID_128_ENCODE(
 0x90e2c006, 0x3c0d, 0x4ef3, 0x9d78, 0x574cd1a64087));
static struct k_spinlock alarm_lock;
static struct bt_conn *alarm_peer;
static struct bt_gatt_discover_params alarm_discovery;
static struct bt_gatt_subscribe_params alarm_subscription;
static struct bt_gatt_write_params alarm_write;
static uint8_t alarm_command[6];
static uint16_t alarm_start, alarm_end, alarm_control_handle, alarm_ack_handle, alarm_ack_end, alarm_ccc;
static bool alarm_closed = true, alarm_discovering, alarm_subscribing, alarm_live, alarm_ready;
static bool alarm_pending, alarm_write_active, alarm_received, alarm_target, alarm_active, alarm_known;
static int alarm_setup_error, alarm_result, alarm_write_error;
static uint32_t alarm_sequence;
static uint32_t alarm_events, alarm_generation;
static uint8_t alarm_source, alarm_output_status;
static int64_t alarm_ack_time;
K_SEM_DEFINE(alarm_setup_done, 0, 1);
K_SEM_DEFINE(alarm_write_done, 0, 1);
K_SEM_DEFINE(alarm_reply_done, 0, 1);

static uint8_t alarm_discovered(struct bt_conn *conn, const struct bt_gatt_attr *attr,
                                struct bt_gatt_discover_params *params)
{
 k_spinlock_key_t key = k_spin_lock(&alarm_lock);
 uint8_t action = BT_GATT_ITER_CONTINUE;
 if (conn != alarm_peer || alarm_closed) { attr = NULL; alarm_setup_error = -ENOTCONN; }
 if (attr == NULL) { alarm_discovering = false; action = BT_GATT_ITER_STOP; }
 else if (params->type == BT_GATT_DISCOVER_PRIMARY) {
  const struct bt_gatt_service_val *service = attr->user_data;
  alarm_start = attr->handle + 1; alarm_end = alarm_ack_end = service->end_handle;
  alarm_discovering = false; action = BT_GATT_ITER_STOP;
 } else if (params->type == BT_GATT_DISCOVER_CHARACTERISTIC) {
  const struct bt_gatt_chrc *ch = attr->user_data;
  if (alarm_ack_handle && attr->handle > alarm_ack_handle && alarm_ack_end == alarm_end) { alarm_ack_end = attr->handle - 1; }
  if (bt_uuid_cmp(ch->uuid, &alarm_control_uuid.uuid) == 0) {
   if (alarm_control_handle || !(ch->properties & BT_GATT_CHRC_WRITE)) { alarm_setup_error = -EPROTO; }
   alarm_control_handle = ch->value_handle;
  } else if (bt_uuid_cmp(ch->uuid, &alarm_ack_uuid.uuid) == 0) {
   if (alarm_ack_handle || !(ch->properties & BT_GATT_CHRC_NOTIFY)) { alarm_setup_error = -EPROTO; }
   alarm_ack_handle = ch->value_handle;
  }
 } else { alarm_ccc = attr->handle; alarm_discovering = false; action = BT_GATT_ITER_STOP; }
 if (!alarm_discovering) { k_sem_give(&alarm_setup_done); }
 k_spin_unlock(&alarm_lock, key); return action;
}
static int alarm_discover(struct bt_conn *conn, uint8_t type, const struct bt_uuid *uuid, uint16_t first, uint16_t last)
{
 k_sem_reset(&alarm_setup_done);
 k_spinlock_key_t key = k_spin_lock(&alarm_lock);
 alarm_discovery = (struct bt_gatt_discover_params) {
  .uuid = uuid, .func = alarm_discovered, .start_handle = first, .end_handle = last, .type = type,
 };
 alarm_discovering = true; alarm_setup_error = 0;
 k_spin_unlock(&alarm_lock, key);
 int rc = bt_gatt_discover(conn, &alarm_discovery);
 if (rc) { key = k_spin_lock(&alarm_lock); alarm_discovering = false; k_spin_unlock(&alarm_lock, key); return rc; }
 if (k_sem_take(&alarm_setup_done, K_MSEC(4000))) { return -ETIMEDOUT; }
 key = k_spin_lock(&alarm_lock); rc = alarm_closed ? -ENOTCONN : alarm_setup_error; k_spin_unlock(&alarm_lock, key);
 return rc;
}
static uint8_t alarm_notification(struct bt_conn *conn, struct bt_gatt_subscribe_params *params,
                                  const void *data, uint16_t size)
{
 ARG_UNUSED(params);
 k_spinlock_key_t key = k_spin_lock(&alarm_lock);
 if (conn != alarm_peer) { k_spin_unlock(&alarm_lock, key); return BT_GATT_ITER_STOP; }
 if (data == NULL) {
  alarm_subscribing = alarm_live = alarm_ready = alarm_known = false;
  if (alarm_pending && !alarm_received) { alarm_result = -ENOTCONN; k_sem_give(&alarm_reply_done); }
  k_sem_give(&alarm_setup_done); k_spin_unlock(&alarm_lock, key); return BT_GATT_ITER_STOP;
 }
 const uint8_t *p = data;
 if (!alarm_closed && size == 8 && p[0] == 1 && p[1] <= 1 && p[6] <= 2 &&
     p[7] == 1 && gateway_audio_u32(p + 2) == 0) {
  if (alarm_events != UINT32_MAX) { alarm_events++; }
  alarm_source = 1; alarm_output_status = p[6];
  alarm_active = p[1] != 0; alarm_known = p[6] == 0;
  gateway_robot_alert(true); /* BTN4 stops Wallaby even if speaker output fails. */
  k_spin_unlock(&alarm_lock, key); return BT_GATT_ITER_CONTINUE;
 }
 if (!alarm_closed && alarm_pending && !alarm_received && size == 8 && p[0] == 1 && p[1] <= 1 &&
     p[7] == 0 && p[6] <= 2 && gateway_audio_u32(p + 2) == alarm_sequence &&
     (p[6] != 0 || (p[1] != 0) == alarm_target)) {
  alarm_received = true; alarm_ack_time = k_uptime_get();
  alarm_result = p[6] == 0 ? 0 : p[6] == 1 ? -ENOTSUP : -EIO;
  alarm_active = p[1] != 0; alarm_known = p[6] == 0;
  alarm_source = 2; alarm_output_status = p[6];
  if (p[6] == 0) { gateway_robot_alert(p[1] != 0); }
  k_sem_give(&alarm_reply_done);
 }
 k_spin_unlock(&alarm_lock, key); return BT_GATT_ITER_CONTINUE;
}
static void alarm_subscribed(struct bt_conn *conn, uint8_t error, struct bt_gatt_subscribe_params *params)
{
 ARG_UNUSED(params);
 k_spinlock_key_t key = k_spin_lock(&alarm_lock);
 if (conn == alarm_peer) {
  alarm_subscribing = false; alarm_setup_error = alarm_closed ? -ENOTCONN : error ? -EPROTO : 0;
  if (error) { alarm_live = false; }
  k_sem_give(&alarm_setup_done);
 }
 k_spin_unlock(&alarm_lock, key);
}
int gateway_alarm_prepare(struct bt_conn *conn)
{
 k_spinlock_key_t key = k_spin_lock(&alarm_lock);
 alarm_peer = conn; alarm_closed = false; alarm_ready = alarm_known = false;
 if (alarm_generation != UINT32_MAX) { alarm_generation++; }
 alarm_start = alarm_end = alarm_control_handle = alarm_ack_handle = alarm_ack_end = alarm_ccc = 0;
 k_spin_unlock(&alarm_lock, key);
 int rc = alarm_discover(conn, BT_GATT_DISCOVER_PRIMARY, &alarm_service.uuid, BT_ATT_FIRST_ATTRIBUTE_HANDLE, BT_ATT_LAST_ATTRIBUTE_HANDLE);
 if (rc) { return rc; }
 if (!alarm_start || alarm_start > alarm_end) { return -ENOTSUP; }
 rc = alarm_discover(conn, BT_GATT_DISCOVER_CHARACTERISTIC, NULL, alarm_start, alarm_end);
 if (rc) { return rc; }
 if (!alarm_control_handle || !alarm_ack_handle || alarm_ack_handle >= alarm_ack_end) { return -ENOTSUP; }
 rc = alarm_discover(conn, BT_GATT_DISCOVER_DESCRIPTOR, BT_UUID_GATT_CCC, alarm_ack_handle + 1, alarm_ack_end);
 if (rc) { return rc; }
 if (!alarm_ccc) { return -ENOENT; }
 k_sem_reset(&alarm_setup_done);
 key = k_spin_lock(&alarm_lock);
 memset(&alarm_subscription, 0, sizeof(alarm_subscription));
 alarm_subscription.notify = alarm_notification; alarm_subscription.subscribe = alarm_subscribed;
 alarm_subscription.value_handle = alarm_ack_handle; alarm_subscription.ccc_handle = alarm_ccc;
 alarm_subscription.value = BT_GATT_CCC_NOTIFY;
 atomic_set_bit(alarm_subscription.flags, BT_GATT_SUBSCRIBE_FLAG_VOLATILE);
 alarm_subscribing = alarm_live = true; alarm_setup_error = 0;
 k_spin_unlock(&alarm_lock, key);
 rc = bt_gatt_subscribe(conn, &alarm_subscription);
 if (rc) { key = k_spin_lock(&alarm_lock); alarm_subscribing = alarm_live = false; k_spin_unlock(&alarm_lock, key); return rc; }
 if (k_sem_take(&alarm_setup_done, K_MSEC(4000))) { return -ETIMEDOUT; }
 key = k_spin_lock(&alarm_lock);
 rc = alarm_closed || !alarm_live ? -ENOTCONN : alarm_setup_error; alarm_ready = rc == 0;
 k_spin_unlock(&alarm_lock, key); return rc;
}
void gateway_alarm_disconnected(struct bt_conn *conn)
{
 k_spinlock_key_t key = k_spin_lock(&alarm_lock);
 if (conn == alarm_peer) {
  alarm_closed = true; alarm_ready = alarm_known = false;
  if (!alarm_received) { alarm_result = -ENOTCONN; }
  k_sem_give(&alarm_reply_done); k_sem_give(&alarm_write_done); k_sem_give(&alarm_setup_done);
 }
 k_spin_unlock(&alarm_lock, key);
}
bool gateway_alarm_drained(void)
{
 k_spinlock_key_t key = k_spin_lock(&alarm_lock);
 bool value = !alarm_discovering && !alarm_subscribing && !alarm_live && !alarm_pending && !alarm_write_active;
 k_spin_unlock(&alarm_lock, key); return value;
}
static void alarm_written(struct bt_conn *conn, uint8_t error, struct bt_gatt_write_params *params)
{
 ARG_UNUSED(params);
 k_spinlock_key_t key = k_spin_lock(&alarm_lock);
 if (conn == alarm_peer) {
  alarm_write_active = false; alarm_write_error = alarm_closed ? -ENOTCONN : error ? -EIO : 0;
  k_sem_give(&alarm_write_done);
 }
 k_spin_unlock(&alarm_lock, key);
}
int gateway_alarm_set(bool active)
{
 if (active) { gateway_robot_alert(true); }
 k_spinlock_key_t key = k_spin_lock(&alarm_lock);
 if (!alarm_ready || alarm_closed || alarm_peer == NULL) { k_spin_unlock(&alarm_lock, key); return -ENOTSUP; }
 if (alarm_pending || alarm_write_active) { k_spin_unlock(&alarm_lock, key); return -EBUSY; }
 alarm_sequence++; if (!alarm_sequence) { alarm_sequence++; }
 alarm_pending = alarm_write_active = true; alarm_received = false; alarm_target = active; alarm_known = false;
 alarm_result = alarm_write_error = -EINPROGRESS;
 alarm_command[0] = 1; alarm_command[1] = active;
 for (size_t i = 0; i < 4; i++) { alarm_command[i+2] = alarm_sequence >> (8*i); }
 struct bt_conn *conn = bt_conn_ref(alarm_peer);
 alarm_write = (struct bt_gatt_write_params) {
  .func = alarm_written, .handle = alarm_control_handle, .data = alarm_command, .length = sizeof(alarm_command),
 };
 k_sem_reset(&alarm_write_done); k_sem_reset(&alarm_reply_done);
 k_spin_unlock(&alarm_lock, key);
 int64_t deadline = k_uptime_get() + 4000;
 int rc = bt_gatt_write(conn, &alarm_write);
 if (rc) { key = k_spin_lock(&alarm_lock); alarm_write_active = false; k_spin_unlock(&alarm_lock, key); }
 else if (k_sem_take(&alarm_write_done, K_MSEC(MAX(0, deadline-k_uptime_get())))) { rc = -ETIMEDOUT; }
 else { key = k_spin_lock(&alarm_lock); rc = alarm_write_error; k_spin_unlock(&alarm_lock, key); }
 if (rc == 0 && k_sem_take(&alarm_reply_done, K_MSEC(MAX(0, deadline-k_uptime_get())))) { rc = -ETIMEDOUT; }
 key = k_spin_lock(&alarm_lock);
 if (alarm_received && alarm_ack_time <= deadline) { rc = alarm_result; }
 bool disconnect = alarm_write_active || (!alarm_received && rc != 0);
 alarm_pending = false;
 if (disconnect) { alarm_ready = alarm_known = false; }
 k_spin_unlock(&alarm_lock, key);
 if (disconnect) { (void)bt_conn_disconnect(conn, BT_HCI_ERR_REMOTE_USER_TERM_CONN); }
 bt_conn_unref(conn); return rc;
}
int gateway_alarm_status(char *json, size_t capacity)
{
 k_spinlock_key_t key = k_spin_lock(&alarm_lock);
 bool available = alarm_ready && !alarm_closed, known = alarm_known, active = alarm_active;
 uint32_t events = alarm_events, generation = alarm_generation;
 uint8_t source = alarm_source, status = alarm_output_status;
 k_spin_unlock(&alarm_lock, key);
 int n = snprintf(json, capacity, "{\"available\":%s,\"active\":%s,\"acknowledged\":%s,"
                  "\"eventCounter\":%lu,\"generation\":%lu,\"source\":\"%s\",\"outputStatus\":%u}",
                  available ? "true" : "false", known ? active ? "true" : "false" : "null", known ? "true" : "false",
                  (unsigned long)events, (unsigned long)generation, source == 1 ? "button" : source == 2 ? "command" : "none", status);
 return n < 0 || (size_t)n >= capacity ? -ENOSPC : n;
}
```
